# MSP430G2X12 register map
Vendor: msp430gen; File version: v0.4.0-16-g4f822b9
Registers are 8-bit, read-write, reset 0x0 unless marked. A register's access mark holds for its fields unless they carry their own. Offsets are from the block's base; [hi:lo] are bit positions; {n}, {i} and the like mark numbered series.

## COMPARATOR_A
Base 0x00000058
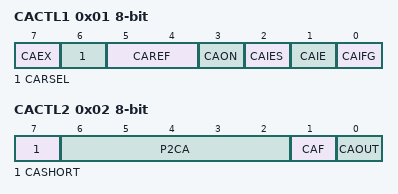
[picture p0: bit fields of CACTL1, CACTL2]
0x01 CACTL1 — Comparator A Control 1
  [7] CAEX — Comp. A Exchange Inputs
  [6] CARSEL — Comp. A Internal Reference Enable
  [5:4] CAREF — Comp. A Internal Reference Select 0
    0=Comp. A Int. Ref. Select 0 : Off; 1=Comp. A Int. Ref. Select 1 : 0.25*Vcc; 2=Comp. A Int. Ref. Select 2 : 0.5*Vcc; 3=Comp. A Int. Ref. Select 3 : Vt
  [3] CAON — Comp. A enable
  [2] CAIES — Comp. A Int. Edge Select: 0:rising / 1:falling
  [1] CAIE — Comp. A Interrupt Enable
  [0] CAIFG — Comp. A Interrupt Flag
0x02 CACTL2 — Comparator A Control 2
  [7] CASHORT — Comp. A Short + and - Terminals
  [6:2] P2CA — Comp. A +Terminal Multiplexer
    0=NONE_NONE (No + or - connection); 1=CA0_NONE (Connect + to CA0, no connection to -); 2=NONE_CA1 (No connection to +, connect - to CA1); 3=CA0_CA1 (Connect + to CA0, connect - to CA1); 4=NONE_CA2 (No connection to +, connect - to CA2); 5=CA0_CA2 (Connect + to CA0, connect - to CA2); 6=NONE_CA3 (No connection to +, connect - to CA3); 7=CA0_CA3 (Connect + to CA0, connect - to CA3); 8=NONE_CA4 (No connection to +, connect - to CA4); 9=CA0_CA4 (Connect + to CA0, connect - to CA4); 10=NONE_CA5 (No connection to +, connect - to CA5); 11=CA0_CA5 (Connect + to CA0, connect - to CA5); 12=NONE_CA6 (No connection to +, connect - to CA6); 13=CA0_CA6 (Connect + to CA0, connect - to CA6); 14=NONE_CA7 (No connection to +, connect - to CA7); 15=CA0_CA7 (Connect + to CA0, connect - to CA7); 16=CA1_NONE (Connect + to CA1, no connection to -); 17=CA2_NONE (Connect + to CA2, no connection to -); 18=CA1_CA1 (Connect + to CA1, connect - to CA1); 19=CA2_CA1 (Connect + to CA2, connect - to CA1); 20=CA1_CA2 (Connect + to CA1, connect - to CA2); 21=CA2_CA2 (Connect + to CA2, connect - to CA2); 22=CA1_CA3 (Connect + to CA1, connect - to CA3); 23=CA2_CA3 (Connect + to CA2, connect - to CA3); 24=CA1_CA4 (Connect + to CA1, connect - to CA4); 25=CA2_CA4 (Connect + to CA2, connect - to CA4); 26=CA1_CA5 (Connect + to CA1, connect - to CA5); 27=CA2_CA5 (Connect + to CA2, connect - to CA5); 28=CA1_CA6 (Connect + to CA1, connect - to CA6); 29=CA2_CA6 (Connect + to CA2, connect - to CA6); 30=CA1_CA7 (Connect + to CA1, connect - to CA7); 31=CA2_CA7 (Connect + to CA2, connect - to CA7)
  [1] CAF — Comp. A Enable Output Filter
  [0] CAOUT — Comp. A Output
0x03 CAPD — Comparator A Port Disable
  [7] CAPD7 — Comp. A Disable Input Buffer of Port Register .7
  [6] CAPD6 — Comp. A Disable Input Buffer of Port Register .6
  [5] CAPD5 — Comp. A Disable Input Buffer of Port Register .5
  [4] CAPD4 — Comp. A Disable Input Buffer of Port Register .4
  [3] CAPD3 — Comp. A Disable Input Buffer of Port Register .3
  [2] CAPD2 — Comp. A Disable Input Buffer of Port Register .2
  [1] CAPD1 — Comp. A Disable Input Buffer of Port Register .1
  [0] CAPD0 — Comp. A Disable Input Buffer of Port Register .0
  [7:0] CAPD — Comparator A Port Disable register

## USI
Base 0x00000078
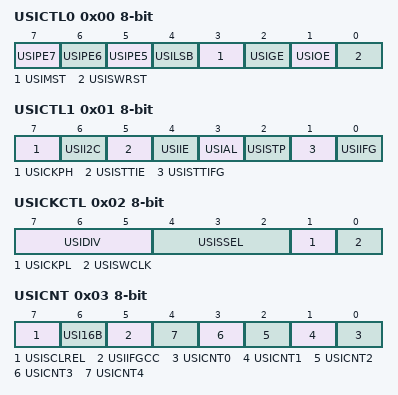
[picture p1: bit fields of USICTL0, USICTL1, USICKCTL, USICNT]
0x00 USICTL0 — USI Control Register 0
  [7] USIPE7 — USI Port Enable Px.7
  [6] USIPE6 — USI Port Enable Px.6
  [5] USIPE5 — USI Port Enable Px.5
  [4] USILSB — USI LSB first 1:LSB / 0:MSB
  [3] USIMST — USI Master Select 0:Slave / 1:Master
  [2] USIGE — USI General Output Enable Latch
  [1] USIOE — USI Output Enable
  [0] USISWRST — USI Software Reset
0x01 USICTL1 — USI Control Register 1
  [7] USICKPH — USI Sync. Mode: Clock Phase
  [6] USII2C — USI I2C Mode
  [5] USISTTIE — USI START Condition interrupt enable
  [4] USIIE — USI Counter Interrupt enable
  [3] USIAL — USI Arbitration Lost
  [2] USISTP — USI STOP Condition received
  [1] USISTTIFG — USI START Condition interrupt Flag
  [0] USIIFG — USI Counter Interrupt Flag
0x02 USICKCTL — USI Clock Control Register
  [7:5] USIDIV — USI Clock Divider 2
    {v}=USI Clock Divider: {v} (v=0..7)
  [4:2] USISSEL — USI Clock Source Select 2
    {v}=USI Clock Source: {v} (v=0..7)
  [1] USICKPL — USI Clock Polarity 0:Inactive=Low / 1:Inactive=High
  [0] USISWCLK — USI Software Clock
0x03 USICNT — USI Bit Counter Register
  [7] USISCLREL — USI SCL Released
  [6] USI16B — USI 16 Bit Shift Register Enable
  [5] USIIFGCC — USI Interrupt Flag Clear Control
  [n] USICNT{n} (n=0..4) — USI Bit Count {n}
0x04 USISRL — USI Low Byte Shift Register
0x05 USISRH — USI High Byte Shift Register
